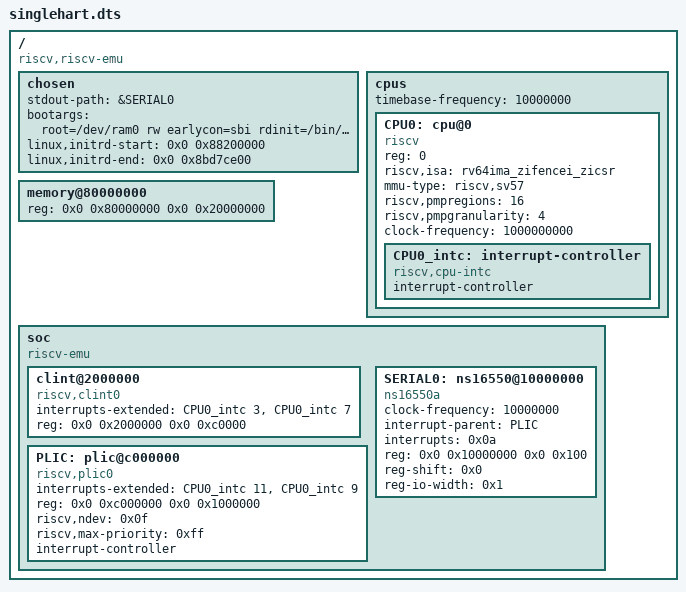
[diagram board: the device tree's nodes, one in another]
/dts-v1/;

/ {
  #address-cells = <2>;
  #size-cells = <2>;
  compatible = "riscv,riscv-emu";
  chosen {
    stdout-path = &SERIAL0;
    bootargs = "root=/dev/ram0 rw earlycon=sbi rdinit=/bin/bash";
    linux,initrd-start = <0x0 0x88200000>;
    linux,initrd-end = <0x0 0x8bd7ce00>;
  };
  cpus {
    #address-cells = <1>;
    #size-cells = <0>;
    timebase-frequency = <10000000>;
    CPU0: cpu@0 {
      device_type = "cpu";
      reg = <0>;
      status = "okay";
      compatible = "riscv";
      riscv,isa = "rv64ima_zifencei_zicsr";
      mmu-type = "riscv,sv57";
      riscv,pmpregions = <16>;
      riscv,pmpgranularity = <4>;
      clock-frequency = <1000000000>;
      CPU0_intc: interrupt-controller {
        #address-cells = <2>;
        #interrupt-cells = <1>;
        interrupt-controller;
        compatible = "riscv,cpu-intc";
      };
    };
  };
  memory@80000000 {
    device_type = "memory";
    reg = <0x0 0x80000000 0x0 0x20000000>;
  };
  soc {
    #address-cells = <2>;
    #size-cells = <2>;
    compatible = "riscv-emu", "simple-bus";
    ranges;
    clint@2000000 {
      compatible = "riscv,clint0";
      interrupts-extended = <&CPU0_intc 3 &CPU0_intc 7 >;
      reg = <0x0 0x2000000 0x0 0xc0000>;
    };
    PLIC: plic@c000000 {
      compatible = "riscv,plic0";
      #address-cells = <2>;
      interrupts-extended = <&CPU0_intc 11 &CPU0_intc 9 >;
      reg = <0x0 0xc000000 0x0 0x1000000>;
      riscv,ndev = <0x0f>;
      riscv,max-priority = <0xff>;
      #interrupt-cells = <1>;
      interrupt-controller;
    };
    SERIAL0: ns16550@10000000 {
      compatible = "ns16550a";
      clock-frequency = <10000000>;
      interrupt-parent = <&PLIC>;
      interrupts = <0x0a>;
      reg = <0x0 0x10000000 0x0 0x100>;
      reg-shift = <0x0>;
      reg-io-width = <0x1>;
    };
  };
};
